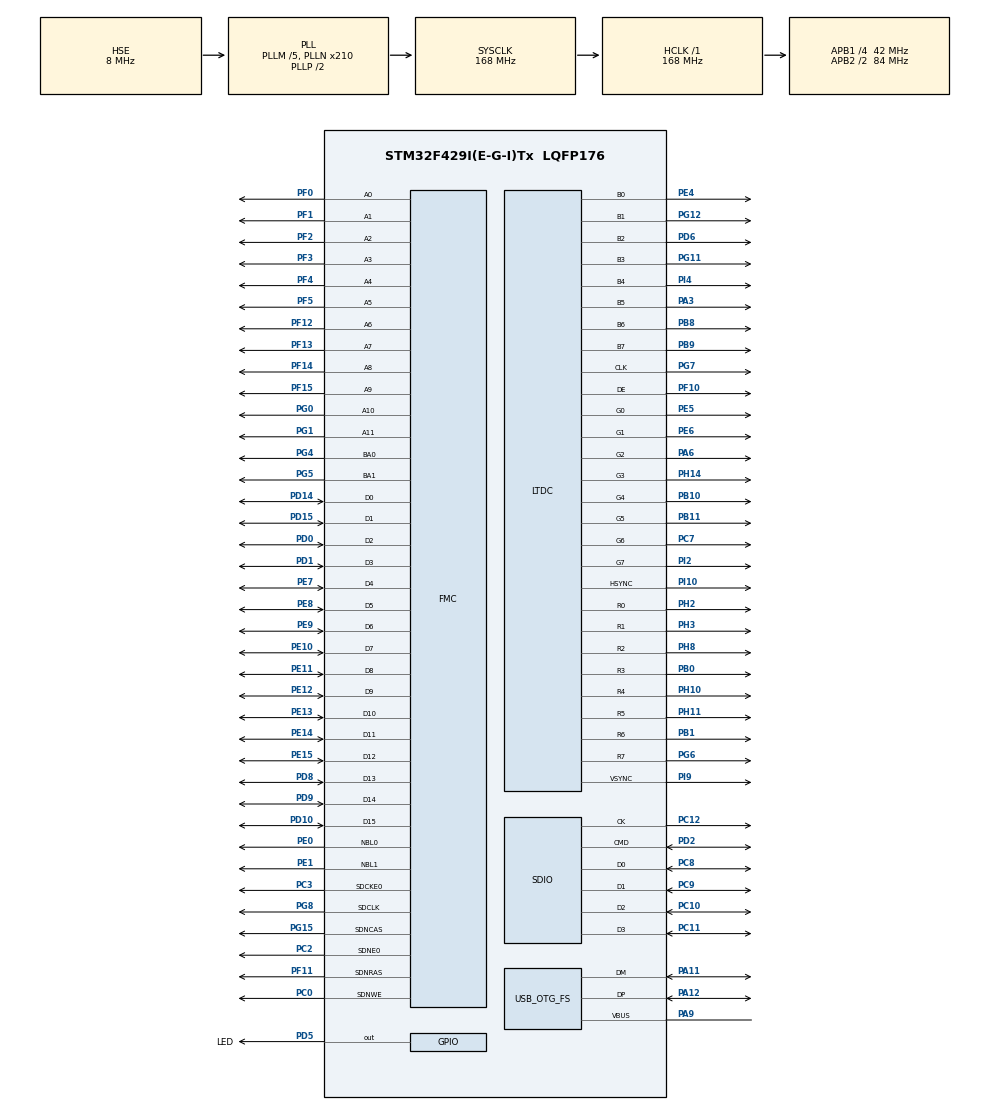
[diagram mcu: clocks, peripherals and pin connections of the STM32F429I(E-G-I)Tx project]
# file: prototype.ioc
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FMC.CASLatency1=FMC_SDRAM_CAS_LATENCY_3
FMC.ExitSelfRefreshDelay1=6
FMC.LoadToActiveDelay1=2
FMC.RCDDelay1=2
FMC.RPDelay1=2
FMC.RPDelay2=2
FMC.ReadPipeDelay1=FMC_SDRAM_RPIPE_DELAY_1
FMC.ReadPipeDelay2=FMC_SDRAM_RPIPE_DELAY_1
FMC.RowBitsNumber1=FMC_SDRAM_ROW_BITS_NUM_12
FMC.RowCycleDelay1=6
FMC.RowCycleDelay2=6
FMC.SDClockPeriod1=FMC_SDRAM_CLOCK_PERIOD_3
FMC.SDClockPeriod2=FMC_SDRAM_CLOCK_PERIOD_3
FMC.SelfRefreshTime1=4
FMC.WriteRecoveryTime1=2
LTDC.ActiveW=800
LTDC.Alpha_L0=255
LTDC.FBStartAdress_L0=0xC0000000
LTDC.HBP=88
LTDC.HFP=40
LTDC.HSync=48
LTDC.ImageHeight_L0=480
LTDC.ImageWidth_L0=800
LTDC.VBP=32
LTDC.VFP=13
LTDC.VSync=3
LTDC.WindowX1_L0=800
LTDC.WindowY1_L0=480
Mcu.Family=STM32F4
Mcu.Name=STM32F429I(E-G-I)Tx
Mcu.Package=LQFP176
NVIC.OTG_FS_IRQn=true\:0\:0\:false
NVIC.PriorityGroup=NVIC_PRIORITYGROUP_4
PA11.Mode=Device_Only
PA11.Signal=USB_OTG_FS_DM
PA12.Mode=Device_Only
PA12.Signal=USB_OTG_FS_DP
PA13.Mode=Trace-Asynchronous_SW
PA13.Signal=SYS_JTMS-SWDIO
PA14.Mode=Trace-Asynchronous_SW
PA14.Signal=SYS_JTCK-SWCLK
PA3.Mode=RGB888
PA3.Signal=LTDC_B5
PA6.Mode=RGB888
PA6.Signal=LTDC_G2
PA9.Mode=Activate_VBUS
PA9.Signal=USB_OTG_FS_VBUS
PB0.Mode=RGB888
PB0.Signal=LTDC_R3
PB1.Mode=RGB888
PB1.Signal=LTDC_R6
PB10.Mode=RGB888
PB10.Signal=LTDC_G4
PB11.Mode=RGB888
PB11.Signal=LTDC_G5
PB3.Mode=Trace-Asynchronous_SW
PB3.Signal=SYS_JTDO-SWO
PB8.Mode=RGB888
PB8.Signal=LTDC_B6
PB9.Mode=RGB888
PB9.Signal=LTDC_B7
PC0.Signal=FMC_SDNWE
PC10.Mode=SD_4_bits_Wide_bus
PC10.Signal=SDIO_D2
PC11.Mode=SD_4_bits_Wide_bus
PC11.Signal=SDIO_D3
PC12.Mode=SD_4_bits_Wide_bus
PC12.Signal=SDIO_CK
PC2.Mode=SdramChipSelect1_1
PC2.Signal=FMC_SDNE0
PC3.Mode=SdramChipSelect1_1
PC3.Signal=FMC_SDCKE0
PC7.Mode=RGB888
PC7.Signal=LTDC_G6
PC8.Mode=SD_4_bits_Wide_bus
PC8.Signal=SDIO_D0
PC9.Mode=SD_4_bits_Wide_bus
PC9.Signal=SDIO_D1
PD0.Signal=FMC_D2_DA2
PD1.Signal=FMC_D3_DA3
PD10.Signal=FMC_D15_DA15
PD14.Signal=FMC_D0_DA0
PD15.Signal=FMC_D1_DA1
PD2.Mode=SD_4_bits_Wide_bus
PD2.Signal=SDIO_CMD
PD5.GPIO_Label=LED
PD5.GPIO_ModeDefaultOutputPP=GPIO_MODE_OUTPUT_PP
PD5.GPIO_PuPd=GPIO_NOPULL
PD5.GPIO_Speed=GPIO_SPEED_LOW
PD5.Signal=GPIO_Output
PD6.Mode=RGB888
PD6.Signal=LTDC_B2
PD8.Signal=FMC_D13_DA13
PD9.Signal=FMC_D14_DA14
PE0.Signal=FMC_NBL0
PE1.Signal=FMC_NBL1
PE10.Signal=FMC_D7_DA7
PE11.Signal=FMC_D8_DA8
PE12.Signal=FMC_D9_DA9
PE13.Signal=FMC_D10_DA10
PE14.Signal=FMC_D11_DA11
PE15.Signal=FMC_D12_DA12
PE4.Mode=RGB888
PE4.Signal=LTDC_B0
PE5.Mode=RGB888
PE5.Signal=LTDC_G0
PE6.Mode=RGB888
PE6.Signal=LTDC_G1
PE7.Signal=FMC_D4_DA4
PE8.Signal=FMC_D5_DA5
PE9.Signal=FMC_D6_DA6
PF0.Signal=FMC_A0
PF1.Signal=FMC_A1
PF10.Mode=RGB888
PF10.Signal=LTDC_DE
PF11.Signal=FMC_SDNRAS
PF12.Signal=FMC_A6
PF13.Signal=FMC_A7
PF14.Signal=FMC_A8
PF15.Signal=FMC_A9
PF2.Signal=FMC_A2
PF3.Signal=FMC_A3
PF4.Signal=FMC_A4
PF5.Signal=FMC_A5
PG0.Signal=FMC_A10
PG1.Signal=FMC_A11
PG11.Mode=RGB888
PG11.Signal=LTDC_B3
PG12.Mode=RGB888
PG12.Signal=LTDC_B1
PG15.Signal=FMC_SDNCAS
PG4.Signal=FMC_A14_BA0
PG5.Signal=FMC_A15_BA1
PG6.Mode=RGB888
PG6.Signal=LTDC_R7
PG7.Mode=RGB888
PG7.Signal=LTDC_CLK
PG8.Signal=FMC_SDCLK
PH0/OSC_IN.Mode=HSE-External-Oscillator
PH0/OSC_IN.Signal=RCC_OSC_IN
PH1/OSC_OUT.Mode=HSE-External-Oscillator
PH1/OSC_OUT.Signal=RCC_OSC_OUT
PH10.Mode=RGB888
PH10.Signal=LTDC_R4
PH11.Mode=RGB888
PH11.Signal=LTDC_R5
PH14.Mode=RGB888
PH14.Signal=LTDC_G3
PH2.Mode=RGB888
PH2.Signal=LTDC_R0
PH3.Mode=RGB888
PH3.Signal=LTDC_R1
PH8.Mode=RGB888
PH8.Signal=LTDC_R2
PI10.Mode=RGB888
PI10.Signal=LTDC_HSYNC
PI2.Mode=RGB888
PI2.Signal=LTDC_G7
PI4.Mode=RGB888
PI4.Signal=LTDC_B4
PI9.Mode=RGB888
PI9.Signal=LTDC_VSYNC
ProjectManager.TargetToolchain=MDK-ARM V5
RCC.48MHZClocksFreq_Value=48000000
RCC.AHBFreq_Value=168000000
RCC.APB1CLKDivider=RCC_HCLK_DIV4
RCC.APB1Freq_Value=42000000
RCC.APB1TimFreq_Value=84000000
RCC.APB2CLKDivider=RCC_HCLK_DIV2
RCC.APB2Freq_Value=84000000
RCC.APB2TimFreq_Value=168000000
RCC.CortexFreq_Value=168000000
RCC.HCLKFreq_Value=168000000
RCC.HSE_VALUE=8000000
RCC.HSI_VALUE=16000000
RCC.LSE_VALUE=32768
RCC.PLLM=5
RCC.PLLN=210
RCC.PLLQ=7
RCC.PLLSAIDivR=RCC_PLLSAIDIVR_8
RCC.PLLSAIN=270
RCC.SYSCLKFreq_VALUE=168000000
RCC.SYSCLKSource=RCC_SYSCLKSOURCE_PLLCLK
RCC.VCOOutputFreq_Value=336000000
SDIO.BusWide=SDIO_BUS_WIDE_1B
SDIO.ClockDiv=2
SDIO.WideMode=SDIO_BUS_WIDE_4B
SH.FMC_A0.0=FMC_A0,12b-sda1
SH.FMC_A1.0=FMC_A1,12b-sda1
SH.FMC_A10.0=FMC_A10,12b-sda1
SH.FMC_A11.0=FMC_A11,12b-sda1
SH.FMC_A14_BA0.0=FMC_BA0,FourSdramBanks1
SH.FMC_A15_BA1.0=FMC_BA1,FourSdramBanks1
SH.FMC_A2.0=FMC_A2,12b-sda1
SH.FMC_A3.0=FMC_A3,12b-sda1
SH.FMC_A4.0=FMC_A4,12b-sda1
SH.FMC_A5.0=FMC_A5,12b-sda1
SH.FMC_A6.0=FMC_A6,12b-sda1
SH.FMC_A7.0=FMC_A7,12b-sda1
SH.FMC_A8.0=FMC_A8,12b-sda1
SH.FMC_A9.0=FMC_A9,12b-sda1
SH.FMC_D0_DA0.0=FMC_D0,sd-16b-d1
SH.FMC_D10_DA10.0=FMC_D10,sd-16b-d1
SH.FMC_D11_DA11.0=FMC_D11,sd-16b-d1
SH.FMC_D12_DA12.0=FMC_D12,sd-16b-d1
SH.FMC_D13_DA13.0=FMC_D13,sd-16b-d1
SH.FMC_D14_DA14.0=FMC_D14,sd-16b-d1
SH.FMC_D15_DA15.0=FMC_D15,sd-16b-d1
SH.FMC_D1_DA1.0=FMC_D1,sd-16b-d1
SH.FMC_D2_DA2.0=FMC_D2,sd-16b-d1
SH.FMC_D3_DA3.0=FMC_D3,sd-16b-d1
SH.FMC_D4_DA4.0=FMC_D4,sd-16b-d1
SH.FMC_D5_DA5.0=FMC_D5,sd-16b-d1
SH.FMC_D6_DA6.0=FMC_D6,sd-16b-d1
SH.FMC_D7_DA7.0=FMC_D7,sd-16b-d1
SH.FMC_D8_DA8.0=FMC_D8,sd-16b-d1
SH.FMC_D9_DA9.0=FMC_D9,sd-16b-d1
SH.FMC_NBL0.0=FMC_NBL0,Sd2ByteEnable1
SH.FMC_NBL1.0=FMC_NBL1,Sd2ByteEnable1
SH.FMC_SDCLK.0=FMC_SDCLK,12b-sda1
SH.FMC_SDNCAS.0=FMC_SDNCAS,12b-sda1
SH.FMC_SDNRAS.0=FMC_SDNRAS,12b-sda1
SH.FMC_SDNWE.0=FMC_SDNWE,12b-sda1
USB_DEVICE.CLASS_NAME-CDC_FS=CDC
USB_DEVICE.MANUFACTURER_STRING-CDC_FS=Oxbern
USB_DEVICE.PRODUCT_STRING_CDC_FS=CCube
USB_DEVICE.USBD_HandleTypeDef-CDC_FS=hUsbDeviceFS
USB_DEVICE.VirtualMode-CDC_FS=Cdc
USB_DEVICE.VirtualModeFS=Cdc_FS
USB_OTG_FS.VirtualMode=Device_Only
VP_CRC_VS_CRC.Mode=CRC_Activate
VP_DMA2D_VS_DMA2D.Mode=DMA2D_Activate
VP_FATFS_VS_SDIO.Mode=SDIO
VP_USB_DEVICE_VS_USB_DEVICE_CDC_FS.Mode=CDC_FS
board=prototype

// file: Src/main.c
/**
  ******************************************************************************
  * File Name          : main.c
  * Description        : Main program body
  ******************************************************************************
  *
  * COPYRIGHT(c) 2015 STMicroelectronics
  *
  * Redistribution and use in source and binary forms, with or without modification,
  * are permitted provided that the following conditions are met:
  *   1. Redistributions of source code must retain the above copyright notice,
  *      this list of conditions and the following disclaimer.
  *   2. Redistributions in binary form must reproduce the above copyright notice,
  *      this list of conditions and the following disclaimer in the documentation
  *      and/or other materials provided with the distribution.
  *   3. Neither the name of STMicroelectronics nor the names of its contributors
  *      may be used to endorse or promote products derived from this software
  *      without specific prior written permission.
  *
  * THIS SOFTWARE IS PROVIDED BY THE COPYRIGHT HOLDERS AND CONTRIBUTORS "AS IS"
  * AND ANY EXPRESS OR IMPLIED WARRANTIES, INCLUDING, BUT NOT LIMITED TO, THE
  * IMPLIED WARRANTIES OF MERCHANTABILITY AND FITNESS FOR A PARTICULAR PURPOSE ARE
  * DISCLAIMED. IN NO EVENT SHALL THE COPYRIGHT HOLDER OR CONTRIBUTORS BE LIABLE
  * FOR ANY DIRECT, INDIRECT, INCIDENTAL, SPECIAL, EXEMPLARY, OR CONSEQUENTIAL
  * DAMAGES (INCLUDING, BUT NOT LIMITED TO, PROCUREMENT OF SUBSTITUTE GOODS OR
  * SERVICES; LOSS OF USE, DATA, OR PROFITS; OR BUSINESS INTERRUPTION) HOWEVER
  * CAUSED AND ON ANY THEORY OF LIABILITY, WHETHER IN CONTRACT, STRICT LIABILITY,
  * OR TORT (INCLUDING NEGLIGENCE OR OTHERWISE) ARISING IN ANY WAY OUT OF THE USE
  * OF THIS SOFTWARE, EVEN IF ADVISED OF THE POSSIBILITY OF SUCH DAMAGE.
  *
  ******************************************************************************
  */
#include "stm32f4xx_hal.h"
#include "fatfs.h"
#include "usb_device.h"

/* USER CODE BEGIN Includes */
#include "usbd_cdc.h"
#include "GUI.h"
/* USER CODE END Includes */

CRC_HandleTypeDef hcrc;

DMA2D_HandleTypeDef hdma2d;

LTDC_HandleTypeDef hltdc;

SD_HandleTypeDef hsd;
HAL_SD_CardInfoTypedef SDCardInfo;

SDRAM_HandleTypeDef hsdram1;

/* USER CODE BEGIN PV */
/* Private variables ---------------------------------------------------------*/
extern USBD_HandleTypeDef hUsbDeviceFS;

FMC_SDRAM_CommandTypeDef command;
#define SDRAM_BANK_ADDR                 ((uint32_t)0xC0000000)
#define SDRAM_MEMORY_WIDTH            FMC_SDRAM_MEM_BUS_WIDTH_16
#define SDCLOCK_PERIOD                FMC_SDRAM_CLOCK_PERIOD_3
#define SDRAM_TIMEOUT     ((uint32_t)0xFFFF)
#define SDRAM_MODEREG_BURST_LENGTH_1             ((uint16_t)0x0000)
#define SDRAM_MODEREG_BURST_LENGTH_2             ((uint16_t)0x0001)
#define SDRAM_MODEREG_BURST_LENGTH_4             ((uint16_t)0x0002)
#define SDRAM_MODEREG_BURST_LENGTH_8             ((uint16_t)0x0004)
#define SDRAM_MODEREG_BURST_TYPE_SEQUENTIAL      ((uint16_t)0x0000)
#define SDRAM_MODEREG_BURST_TYPE_INTERLEAVED     ((uint16_t)0x0008)
#define SDRAM_MODEREG_CAS_LATENCY_2              ((uint16_t)0x0020)
#define SDRAM_MODEREG_CAS_LATENCY_3              ((uint16_t)0x0030)
#define SDRAM_MODEREG_OPERATING_MODE_STANDARD    ((uint16_t)0x0000)
#define SDRAM_MODEREG_WRITEBURST_MODE_PROGRAMMED ((uint16_t)0x0000)
#define SDRAM_MODEREG_WRITEBURST_MODE_SINGLE     ((uint16_t)0x0200)
#define REFRESH_COUNT       ((uint32_t)0x0569)   /* SDRAM refresh counter (84MHz SD clock) */
/* USER CODE END PV */

void SystemClock_Config(void);
static void MX_GPIO_Init(void);
static void MX_CRC_Init(void);
static void MX_DMA2D_Init(void);
static void MX_FMC_Init(void);
static void MX_LTDC_Init(void);
static void MX_SDIO_SD_Init(void);

/* USER CODE BEGIN PFP */
/* Private function prototypes -----------------------------------------------*/
static void SDRAM_Initialization_Sequence(SDRAM_HandleTypeDef *hsdram, FMC_SDRAM_CommandTypeDef *Command);
/* USER CODE END PFP */

int main(void)
{

  /* MCU Configuration----------------------------------------------------------*/

  /* Reset of all peripherals, Initializes the Flash interface and the Systick. */
  HAL_Init();

  /* Configure the system clock */
  SystemClock_Config();

  /* Initialize all configured peripherals */
  MX_GPIO_Init();
  MX_CRC_Init();
  MX_DMA2D_Init();
  MX_FMC_Init();
  MX_LTDC_Init();
  MX_SDIO_SD_Init();
  MX_FATFS_Init();
  MX_USB_DEVICE_Init();

  /* USER CODE BEGIN 2 */
	FIL MyFile;
	if (f_open(&MyFile, "test", FA_READ) != FR_OK)
	{
		USBD_CDC_SetTxBuffer(&hUsbDeviceFS, (uint8_t*)"Failed to open file test\r\n", 27);
		USBD_CDC_TransmitPacket(&hUsbDeviceFS);
	} else {
		uint8_t rtext[100];
		uint32_t bytesread;
		f_read(&MyFile, rtext, sizeof(rtext), &bytesread);
	}

	SDRAM_Initialization_Sequence(&hsdram1, &command);

	GUI_Init();
	GUI_SetColor(GUI_WHITE);
	GUI_SetFont(GUI_FONT_24_ASCII);
	GUI_SelectLayer(0);
	GUI_DispStringHCenterAt("FUCKING FINALLY YOU PIECE OF SHIT", 400, 216);
	GUI_DrawRoundedFrame(200, 216, 600, 240, 5, 2);

  /* USER CODE END 2 */

  /* Infinite loop */
  while (1)
  {

  /* USER CODE BEGIN 3 */
//	USBD_CDC_SetTxBuffer(&hUsbDeviceFS, (uint8_t*)"Hello World!\r\n", 15);
//	USBD_CDC_TransmitPacket(&hUsbDeviceFS);
	HAL_Delay(500);
  }
  /* USER CODE END 3 */

}

/** System Clock Configuration
*/
void SystemClock_Config(void)
{

  RCC_OscInitTypeDef RCC_OscInitStruct;
  RCC_ClkInitTypeDef RCC_ClkInitStruct;
  RCC_PeriphCLKInitTypeDef PeriphClkInitStruct;

  __PWR_CLK_ENABLE();

  __HAL_PWR_VOLTAGESCALING_CONFIG(PWR_REGULATOR_VOLTAGE_SCALE1);

  RCC_OscInitStruct.OscillatorType = RCC_OSCILLATORTYPE_HSE;
  RCC_OscInitStruct.HSEState = RCC_HSE_ON;
  RCC_OscInitStruct.PLL.PLLState = RCC_PLL_ON;
  RCC_OscInitStruct.PLL.PLLSource = RCC_PLLSOURCE_HSE;
  RCC_OscInitStruct.PLL.PLLM = 5;
  RCC_OscInitStruct.PLL.PLLN = 210;
  RCC_OscInitStruct.PLL.PLLP = RCC_PLLP_DIV2;
  RCC_OscInitStruct.PLL.PLLQ = 7;
  HAL_RCC_OscConfig(&RCC_OscInitStruct);

  RCC_ClkInitStruct.ClockType = RCC_CLOCKTYPE_SYSCLK|RCC_CLOCKTYPE_PCLK1
                              |RCC_CLOCKTYPE_PCLK2;
  RCC_ClkInitStruct.SYSCLKSource = RCC_SYSCLKSOURCE_PLLCLK;
  RCC_ClkInitStruct.AHBCLKDivider = RCC_SYSCLK_DIV1;
  RCC_ClkInitStruct.APB1CLKDivider = RCC_HCLK_DIV4;
  RCC_ClkInitStruct.APB2CLKDivider = RCC_HCLK_DIV2;
  HAL_RCC_ClockConfig(&RCC_ClkInitStruct, FLASH_LATENCY_5);

  PeriphClkInitStruct.PeriphClockSelection = RCC_PERIPHCLK_LTDC;
  PeriphClkInitStruct.PLLSAI.PLLSAIN = 270;
  PeriphClkInitStruct.PLLSAI.PLLSAIR = 2;
  PeriphClkInitStruct.PLLSAIDivR = RCC_PLLSAIDIVR_8;
  HAL_RCCEx_PeriphCLKConfig(&PeriphClkInitStruct);

  HAL_SYSTICK_Config(HAL_RCC_GetHCLKFreq()/1000);

  HAL_SYSTICK_CLKSourceConfig(SYSTICK_CLKSOURCE_HCLK);

}

/* CRC init function */
void MX_CRC_Init(void)
{

  hcrc.Instance = CRC;
  HAL_CRC_Init(&hcrc);

}

/* DMA2D init function */
void MX_DMA2D_Init(void)
{

  hdma2d.Instance = DMA2D;
  hdma2d.Init.Mode = DMA2D_M2M;
  hdma2d.Init.ColorMode = DMA2D_ARGB8888;
  hdma2d.Init.OutputOffset = 0;
  hdma2d.LayerCfg[1].InputOffset = 0;
  hdma2d.LayerCfg[1].InputColorMode = CM_ARGB8888;
  hdma2d.LayerCfg[1].AlphaMode = DMA2D_NO_MODIF_ALPHA;
  hdma2d.LayerCfg[1].InputAlpha = 0;
  HAL_DMA2D_Init(&hdma2d);

  HAL_DMA2D_ConfigLayer(&hdma2d, 1);

}

/* LTDC init function */
void MX_LTDC_Init(void)
{

  LTDC_LayerCfgTypeDef pLayerCfg;
  LTDC_LayerCfgTypeDef pLayerCfg1;

  hltdc.Instance = LTDC;
  hltdc.Init.HSPolarity = LTDC_HSPOLARITY_AL;
  hltdc.Init.VSPolarity = LTDC_VSPOLARITY_AL;
  hltdc.Init.DEPolarity = LTDC_DEPOLARITY_AL;
  hltdc.Init.PCPolarity = LTDC_PCPOLARITY_IPC;
  hltdc.Init.HorizontalSync = 47;
  hltdc.Init.VerticalSync = 2;
  hltdc.Init.AccumulatedHBP = 135;
  hltdc.Init.AccumulatedVBP = 34;
  hltdc.Init.AccumulatedActiveW = 935;
  hltdc.Init.AccumulatedActiveH = 514;
  hltdc.Init.TotalWidth = 975;
  hltdc.Init.TotalHeigh = 527;
  hltdc.Init.Backcolor.Blue = 0;
  hltdc.Init.Backcolor.Green = 0;
  hltdc.Init.Backcolor.Red = 0;
  HAL_LTDC_Init(&hltdc);

  pLayerCfg.WindowX0 = 0;
  pLayerCfg.WindowX1 = 800;
  pLayerCfg.WindowY0 = 0;
  pLayerCfg.WindowY1 = 480;
  pLayerCfg.PixelFormat = LTDC_PIXEL_FORMAT_ARGB8888;
  pLayerCfg.Alpha = 255;
  pLayerCfg.Alpha0 = 0;
  pLayerCfg.BlendingFactor1 = LTDC_BLENDING_FACTOR1_CA;
  pLayerCfg.BlendingFactor2 = LTDC_BLENDING_FACTOR2_CA;
  pLayerCfg.FBStartAdress = 0xC0000000;
  pLayerCfg.ImageWidth = 800;
  pLayerCfg.ImageHeight = 480;
  pLayerCfg.Backcolor.Blue = 0;
  pLayerCfg.Backcolor.Green = 0;
  pLayerCfg.Backcolor.Red = 0;
  HAL_LTDC_ConfigLayer(&hltdc, &pLayerCfg, 0);

  pLayerCfg1.WindowX0 = 0;
  pLayerCfg1.WindowX1 = 0;
  pLayerCfg1.WindowY0 = 0;
  pLayerCfg1.WindowY1 = 0;
  pLayerCfg1.PixelFormat = LTDC_PIXEL_FORMAT_ARGB8888;
  pLayerCfg1.Alpha = 0;
  pLayerCfg1.Alpha0 = 0;
  pLayerCfg1.BlendingFactor1 = LTDC_BLENDING_FACTOR1_CA;
  pLayerCfg1.BlendingFactor2 = LTDC_BLENDING_FACTOR2_CA;
  pLayerCfg1.FBStartAdress = 0;
  pLayerCfg1.ImageWidth = 0;
  pLayerCfg1.ImageHeight = 0;
  pLayerCfg1.Backcolor.Blue = 0;
  pLayerCfg1.Backcolor.Green = 0;
  pLayerCfg1.Backcolor.Red = 0;
  HAL_LTDC_ConfigLayer(&hltdc, &pLayerCfg1, 1);

}

/* SDIO init function */
void MX_SDIO_SD_Init(void)
{

  hsd.Instance = SDIO;
  hsd.Init.ClockEdge = SDIO_CLOCK_EDGE_RISING;
  hsd.Init.ClockBypass = SDIO_CLOCK_BYPASS_DISABLE;
  hsd.Init.ClockPowerSave = SDIO_CLOCK_POWER_SAVE_DISABLE;
  hsd.Init.BusWide = SDIO_BUS_WIDE_1B;
  hsd.Init.HardwareFlowControl = SDIO_HARDWARE_FLOW_CONTROL_DISABLE;
  hsd.Init.ClockDiv = 2;

}
/* FMC initialization function */
void MX_FMC_Init(void)
{
  FMC_SDRAM_TimingTypeDef SdramTiming;

  /** Perform the SDRAM1 memory initialization sequence
  */
  hsdram1.Instance = FMC_SDRAM_DEVICE;
  /* hsdram1.Init */
  hsdram1.Init.SDBank = FMC_SDRAM_BANK1;
  hsdram1.Init.ColumnBitsNumber = FMC_SDRAM_COLUMN_BITS_NUM_8;
  hsdram1.Init.RowBitsNumber = FMC_SDRAM_ROW_BITS_NUM_12;
  hsdram1.Init.MemoryDataWidth = FMC_SDRAM_MEM_BUS_WIDTH_16;
  hsdram1.Init.InternalBankNumber = FMC_SDRAM_INTERN_BANKS_NUM_4;
  hsdram1.Init.CASLatency = FMC_SDRAM_CAS_LATENCY_3;
  hsdram1.Init.WriteProtection = FMC_SDRAM_WRITE_PROTECTION_DISABLE;
  hsdram1.Init.SDClockPeriod = FMC_SDRAM_CLOCK_PERIOD_3;
  hsdram1.Init.ReadBurst = FMC_SDRAM_RBURST_DISABLE;
  hsdram1.Init.ReadPipeDelay = FMC_SDRAM_RPIPE_DELAY_1;
  /* SdramTiming */
  SdramTiming.LoadToActiveDelay = 2;
  SdramTiming.ExitSelfRefreshDelay = 6;
  SdramTiming.SelfRefreshTime = 4;
  SdramTiming.RowCycleDelay = 6;
  SdramTiming.WriteRecoveryTime = 2;
  SdramTiming.RPDelay = 2;
  SdramTiming.RCDDelay = 2;

  HAL_SDRAM_Init(&hsdram1, &SdramTiming);

}

/** Configure pins as
        * Analog
        * Input
        * Output
        * EVENT_OUT
        * EXTI
*/
void MX_GPIO_Init(void)
{

  GPIO_InitTypeDef GPIO_InitStruct;

  /* GPIO Ports Clock Enable */
  __GPIOE_CLK_ENABLE();
  __GPIOI_CLK_ENABLE();
  __GPIOF_CLK_ENABLE();
  __GPIOH_CLK_ENABLE();
  __GPIOC_CLK_ENABLE();
  __GPIOA_CLK_ENABLE();
  __GPIOB_CLK_ENABLE();
  __GPIOG_CLK_ENABLE();
  __GPIOD_CLK_ENABLE();

  /*Configure GPIO pin : PD5 */
  GPIO_InitStruct.Pin = GPIO_PIN_5;
  GPIO_InitStruct.Mode = GPIO_MODE_OUTPUT_PP;
  GPIO_InitStruct.Pull = GPIO_NOPULL;
  GPIO_InitStruct.Speed = GPIO_SPEED_LOW;
  HAL_GPIO_Init(GPIOD, &GPIO_InitStruct);

}

/* USER CODE BEGIN 4 */
static void SDRAM_Initialization_Sequence(SDRAM_HandleTypeDef *hsdram, FMC_SDRAM_CommandTypeDef *Command)
{
  __IO uint32_t tmpmrd =0;
  /* Step 3:  Configure a clock configuration enable command */
  Command->CommandMode 			 = FMC_SDRAM_CMD_CLK_ENABLE;
  Command->CommandTarget 		 = FMC_SDRAM_CMD_TARGET_BANK1;
  Command->AutoRefreshNumber 	 = 1;
  Command->ModeRegisterDefinition = 0;

  /* Send the command */
  HAL_SDRAM_SendCommand(hsdram, Command, 0x1000);

  /* Step 4: Insert 100 ms delay */
  HAL_Delay(100);

  /* Step 5: Configure a PALL (precharge all) command */
  Command->CommandMode 			 = FMC_SDRAM_CMD_PALL;
  Command->CommandTarget 	     = FMC_SDRAM_CMD_TARGET_BANK1;
  Command->AutoRefreshNumber 	 = 1;
  Command->ModeRegisterDefinition = 0;

  /* Send the command */
  HAL_SDRAM_SendCommand(hsdram, Command, 0x1000);

  /* Step 6 : Configure a Auto-Refresh command */
  Command->CommandMode 			 = FMC_SDRAM_CMD_AUTOREFRESH_MODE;
  Command->CommandTarget 		 = FMC_SDRAM_CMD_TARGET_BANK1;
  Command->AutoRefreshNumber 	 = 4;
  Command->ModeRegisterDefinition = 0;

  /* Send the command */
  HAL_SDRAM_SendCommand(hsdram, Command, 0x1000);

  /* Step 7: Program the external memory mode register */
  tmpmrd = (uint32_t)SDRAM_MODEREG_BURST_LENGTH_2          |
                     SDRAM_MODEREG_BURST_TYPE_SEQUENTIAL   |
                     SDRAM_MODEREG_CAS_LATENCY_3           |
                     SDRAM_MODEREG_OPERATING_MODE_STANDARD |
                     SDRAM_MODEREG_WRITEBURST_MODE_SINGLE;

  Command->CommandMode = FMC_SDRAM_CMD_LOAD_MODE;
  Command->CommandTarget 		 = FMC_SDRAM_CMD_TARGET_BANK1;
  Command->AutoRefreshNumber 	 = 1;
  Command->ModeRegisterDefinition = tmpmrd;

  /* Send the command */
  HAL_SDRAM_SendCommand(hsdram, Command, 0x1000);

  /* Step 8: Set the refresh rate counter */
  /* (15.62 us x Freq) - 20 */
  /* Set the device refresh counter */
  HAL_SDRAM_ProgramRefreshRate(hsdram, REFRESH_COUNT);
}
/* USER CODE END 4 */

/************************ (C) COPYRIGHT STMicroelectronics *****END OF FILE****/
